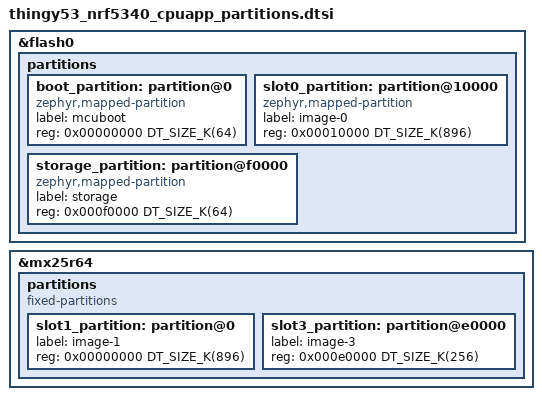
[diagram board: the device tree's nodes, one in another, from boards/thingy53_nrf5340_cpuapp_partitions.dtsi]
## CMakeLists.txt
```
#
# Copyright (c) 2022 Nordic Semiconductor ASA
#
# SPDX-License-Identifier: LicenseRef-Nordic-5-Clause
#

cmake_minimum_required(VERSION 3.20.0)

find_package(Zephyr REQUIRED HINTS $ENV{ZEPHYR_BASE})
project(nrf_wifi_scan)

target_include_directories(app PUBLIC ${ZEPHYR_BASE}/subsys/net/ip)

target_sources(app PRIVATE src/main.c)
```

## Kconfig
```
#
# Copyright (c) 2023 Nordic Semiconductor
#
# SPDX-License-Identifier: LicenseRef-Nordic-5-Clause
#

source "Kconfig.zephyr"

menu "Nordic Scan sample"

config WIFI_SCAN_INTERVAL_S
	int "Scan interval (seconds)"
	default 10
	help
	  Specifies the scan interval in seconds.

config WIFI_SCAN_BANDS_LIST
	string "Frequency bands to scan"
	default "2" if WIFI_SCAN_PROFILE_2_4GHz_ACTIVE || WIFI_SCAN_PROFILE_2_4GHz_PASSIVE || WIFI_SCAN_PROFILE_2_4GHz_NON_OVERLAP_CHAN
	default "5" if WIFI_SCAN_PROFILE_5GHz_ACTIVE || WIFI_SCAN_PROFILE_5GHz_PASSIVE || WIFI_SCAN_PROFILE_5GHz_NON_DFS_CHAN
	default "2,5" if WIFI_SCAN_PROFILE_2_4GHz_NON_OVERLAP_AND_5GHz_NON_DFS_CHAN
	default ""
	help
	  Specifies the frequency bands to scan, as follows:
	  2 - 2.4 GHz,
	  5 - 5 GHz,
	  6 - 6 GHz,
	  "" - All bands allowed by the regulatory domain.
	  Multiple bands can be specified as comma separated band values.
	  Only regulatory domain permitted values are allowed.

config WIFI_SCAN_CHAN_LIST
	string "Channel list for scan"
	default "2:1,6,11" if WIFI_SCAN_PROFILE_2_4GHz_NON_OVERLAP_CHAN
	default "5:36,40,44,48,149,153,157,161,165" if WIFI_SCAN_PROFILE_5GHz_NON_DFS_CHAN
	default "2:1,6,11_5:36,40,44,48,149,153,157,161,165" if WIFI_SCAN_PROFILE_2_4GHz_NON_OVERLAP_AND_5GHz_NON_DFS_CHAN
	default ""
	help
	  Specifies the list of channels used to perform scan.

config WIFI_SCAN_DWELL_TIME_ACTIVE
	int "Active scan dwell time"
	default 50
	range 5 1000
	help
	  Active scan dwell time (in ms) per channel.

config WIFI_SCAN_DWELL_TIME_PASSIVE
	int "Passive scan dwell time"
	default 130
	range 10 1000
	help
	  Passive scan dwell time (in ms) per channel.

# Hidden options to select the scan type
config WIFI_SCAN_TYPE_ACTIVE
	bool

config WIFI_SCAN_TYPE_PASSIVE
	bool

choice
	prompt "Choose a WiFi Scan Profile"

config WIFI_SCAN_PROFILE_DEFAULT
	bool "Scan in all bands and channels"
	help
	  Enable this profile to do Wi-Fi scan in all supported bands and channels.

config WIFI_SCAN_PROFILE_ACTIVE
	bool "Active scan"
	select WIFI_SCAN_TYPE_ACTIVE
	help
	  Enable this profile to do active scan where allowed.

config WIFI_SCAN_PROFILE_PASSIVE
	bool "Passive scan"
	select WIFI_SCAN_TYPE_PASSIVE
	help
	  Enable this profile to do passive scan on all channels.

config WIFI_SCAN_PROFILE_2_4GHz_ACTIVE
	bool "Scan in the 2.4 GHz band using active scan"
	select WIFI_SCAN_TYPE_ACTIVE
	help
	  Enable this profile to scan in the 2.4 GHz band using active scanning where allowed.

config WIFI_SCAN_PROFILE_2_4GHz_PASSIVE
	bool "Scan in the 2.4 GHz band using passive scan"
	select WIFI_SCAN_TYPE_PASSIVE
	help
	  Enable this profile to scan in the 2.4 GHz band using passive scanning on all channels.

config WIFI_SCAN_PROFILE_5GHz_ACTIVE
	bool "Scan in the 5 GHz band using active scan"
	select WIFI_SCAN_TYPE_ACTIVE
	help
	  Enable this profile to scan in the 5 GHz band using active scanning where allowed.

config WIFI_SCAN_PROFILE_5GHz_PASSIVE
	bool "Scan in the 5 GHz band using passive scan"
	select WIFI_SCAN_TYPE_PASSIVE
	help
	  Enable this profile to scan in the 5 GHz band using passive scanning on all channels.

config WIFI_SCAN_PROFILE_2_4GHz_NON_OVERLAP_CHAN
	bool "Scan only non-overlapping channels"
	help
	  Enable this profile to scan only non-overlapping channels (1, 6, 11)
	  in the 2.4 GHz band.

config WIFI_SCAN_PROFILE_5GHz_NON_DFS_CHAN
	bool "Scan only non-DFS channels"
	help
	  Enable this profile to scan only non-DFS channels (36, 40, 44,
	  48, 149, 153, 157, 161, 165) in the 5 GHz band.

config WIFI_SCAN_PROFILE_2_4GHz_NON_OVERLAP_AND_5GHz_NON_DFS_CHAN
	bool "Scan only non-overlapping and non-DFS channels"
	help
	  Enable this profile to scan only non-overlapping channels
	  (1, 6, 11) in the 2.4 GHz band and non-DFS channels (36, 40, 44,
	  48, 149, 153, 157, 161, 165) in the 5 GHz band.

endchoice

endmenu
```

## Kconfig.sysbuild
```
#
# Copyright (c) 2026 Nordic Semiconductor ASA
#
# SPDX-License-Identifier: LicenseRef-Nordic-5-Clause
#

source "${ZEPHYR_NRF_MODULE_DIR}/samples/wifi/Kconfig.sysbuild.nrf70"

source "share/sysbuild/Kconfig"
```

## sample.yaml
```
sample:
  description: Wi-Fi scan sample application
  name: Wi-Fi scan
tests:
  sample.nrf7002dk.scan:
    sysbuild: true
    build_only: true
    integration_platforms:
      - nrf7002dk/nrf5340/cpuapp
    platform_allow:
      - nrf7002dk/nrf5340/cpuapp
    tags:
      - ci_build
      - sysbuild
      - ci_samples_wifi
  sample.nrf7000_eks.scan:
    sysbuild: true
    build_only: true
    extra_args: SHIELD=nrf7002ek_nrf7000
    integration_platforms:
      - nrf5340dk/nrf5340/cpuapp
      - nrf52840dk/nrf52840
      - nrf9160dk/nrf9160/ns
      - nrf9161dk/nrf9161/ns
    platform_allow:
      - nrf5340dk/nrf5340/cpuapp
      - nrf52840dk/nrf52840
      - nrf9160dk/nrf9160/ns
      - nrf9161dk/nrf9161/ns
    tags:
      - ci_build
      - sysbuild
      - ci_samples_wifi
  sample.nrf7000_eks.raw_scan:
    sysbuild: true
    build_only: true
    extra_args:
      - SHIELD=nrf7002ek_nrf7000
      - CONFIG_WIFI_MGMT_RAW_SCAN_RESULTS=y
    integration_platforms:
      - nrf9160dk/nrf9160/ns
      - nrf9161dk/nrf9161/ns
    platform_allow:
      - nrf9160dk/nrf9160/ns
      - nrf9161dk/nrf9161/ns
      - nrf9151dk/nrf9151/ns
    tags:
      - ci_build
      - sysbuild
      - ci_samples_wifi
  sample.nrf7002_eb.thingy53.scan:
    sysbuild: true
    build_only: true
    extra_args: scan_SHIELD=nrf7002eb
    integration_platforms:
      - thingy53/nrf5340/cpuapp
    platform_allow: thingy53/nrf5340/cpuapp
    tags:
      - ci_build
      - sysbuild
      - ci_samples_wifi
  sample.thingy91x_nrf7000.scan:
    sysbuild: true
    build_only: true
    integration_platforms:
      - thingy91x/nrf9151/ns
    platform_allow: thingy91x/nrf9151/ns
    extra_args:
      - SB_CONFIG_WIFI_NRF70_SCAN_ONLY=y
    tags:
      - ci_build
      - sysbuild
      - ci_samples_wifi
  sample.nrf7002eb_interposer_p1.nrf7002eb.scan:
    sysbuild: true
    build_only: true
    extra_args:
      - scan_SHIELD="nrf7002eb_interposer_p1;nrf7002eb"
      - scan_SNIPPET=nrf70-wifi
    integration_platforms:
      - nrf54h20dk/nrf54h20/cpuapp
      - nrf54l15dk/nrf54l15/cpuapp
    platform_allow:
      - nrf54h20dk/nrf54h20/cpuapp
      - nrf54l15dk/nrf54l15/cpuapp
    tags:
      - ci_build
      - sysbuild
      - ci_samples_wifi
  sample.nrf7002eb2.scan:
    sysbuild: true
    build_only: true
    extra_args:
      - scan_SHIELD="nrf7002eb2"
      - SNIPPET=nrf70-wifi
    integration_platforms:
      - nrf54l15dk/nrf54l15/cpuapp
    platform_allow:
      - nrf54l15dk/nrf54l15/cpuapp
    tags:
      - ci_build
      - sysbuild
      - ci_samples_wifi
  sample.54lm20dk.nrf7002eb2.scan:
    sysbuild: true
    build_only: true
    extra_args:
      - scan_SHIELD="nrf7002eb2"
    integration_platforms:
      - nrf54lm20dk/nrf54lm20a/cpuapp
      - nrf54lm20dk/nrf54lm20b/cpuapp
    platform_allow:
      - nrf54lm20dk/nrf54lm20a/cpuapp
      - nrf54lm20dk/nrf54lm20b/cpuapp
    tags:
      - ci_build
      - sysbuild
      - ci_samples_wifi
  sample.nrf7120.scan:
    sysbuild: true
    build_only: true
    extra_args:
      - EXTRA_DTC_OVERLAY_FILE=${ZEPHYR_NRFXLIB_MODULE_DIR}/nrf71_wifi/bins/0.1.0/nrf7120_wifi_patch.dtsi
      - CONFIG_WIFI_NRF71_PATCH=y
    integration_platforms:
      - nrf7120dk/nrf7120/cpuapp
      - nrf7120dk/nrf7120/cpuapp/ns
    platform_allow:
      - nrf7120dk/nrf7120/cpuapp
      - nrf7120dk/nrf7120/cpuapp/ns
    tags:
      - ci_build
      - sysbuild
      - ci_samples_nrf71_wifi
```

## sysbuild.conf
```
#
# Copyright (c) 2024 Nordic Semiconductor ASA
#
# SPDX-License-Identifier: LicenseRef-Nordic-5-Clause
#

SB_CONFIG_WIFI_NRF70_SCAN_ONLY=y
```

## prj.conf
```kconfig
#
# Copyright (c) 2022 Nordic Semiconductor ASA
#
# SPDX-License-Identifier: LicenseRef-Nordic-5-Clause
#
CONFIG_WIFI=y
CONFIG_NET_L2_WIFI_MGMT=y

# System settings
CONFIG_ASSERT=y

# Networking
CONFIG_NETWORKING=y
CONFIG_NET_BUF_RX_COUNT=1
CONFIG_NET_BUF_TX_COUNT=1
CONFIG_NET_L2_ETHERNET=y
CONFIG_NET_NATIVE=n
CONFIG_NET_OFFLOAD=y

CONFIG_INIT_STACKS=y

# Memories
CONFIG_MAIN_STACK_SIZE=5200

# Debugging
CONFIG_STACK_SENTINEL=y
CONFIG_DEBUG_COREDUMP=y
CONFIG_DEBUG_COREDUMP_BACKEND_LOGGING=y
CONFIG_DEBUG_COREDUMP_MEMORY_DUMP_MIN=y

# Logging
CONFIG_LOG=y
CONFIG_PRINTK=y
# If below config is enabled, printk logs are
# buffered. For unbuffered messages, disable this.
CONFIG_LOG_PRINTK=n

# printing of scan results puts pressure on queues in new locking
# design in net_mgmt. So, use a higher timeout for a crowded
# environment.
CONFIG_NET_MGMT_EVENT_QUEUE_TIMEOUT=5000

# Raw scan Options
CONFIG_WIFI_MGMT_RAW_SCAN_RESULTS=n
CONFIG_WIFI_MGMT_RAW_SCAN_RESULTS_ONLY=n

CONFIG_WIFI_SCAN_DWELL_TIME_ACTIVE=50
CONFIG_WIFI_SCAN_DWELL_TIME_PASSIVE=130
```

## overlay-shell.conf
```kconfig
#
# Copyright (c) 2024 Nordic Semiconductor ASA
#
# SPDX-License-Identifier: LicenseRef-Nordic-5-Clause
#

CONFIG_SHELL=y
CONFIG_NET_SHELL=n
CONFIG_SHELL_BACKEND_SERIAL=y
CONFIG_SHELL_STACK_SIZE=5200
CONFIG_NRF70_UTIL=y
CONFIG_SYS_HEAP_RUNTIME_STATS=y
CONFIG_LOG=y
CONFIG_LOG_MODE_IMMEDIATE=y
CONFIG_PRINTK=y
```

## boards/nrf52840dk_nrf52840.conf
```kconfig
# Copyright (c) 2026 Nordic Semiconductor ASA
#
# SPDX-License-Identifier: LicenseRef-Nordic-5-Clause

#NRF70 specific configuration
CONFIG_WIFI_NRF70=y
```

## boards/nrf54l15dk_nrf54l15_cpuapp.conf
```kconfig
# Copyright (c) 2026 Nordic Semiconductor ASA
#
# SPDX-License-Identifier: LicenseRef-Nordic-5-Clause
#

#NRF70 specific configuration
CONFIG_WIFI_NRF70=y
```

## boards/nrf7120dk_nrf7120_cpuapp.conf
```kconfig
#
# Copyright (c) 2026 Nordic Semiconductor
#
# SPDX-License-Identifier: LicenseRef-Nordic-5-Clause
#

CONFIG_WIFI_NRF71=y
CONFIG_WIFI_USAGE_MODE_SCAN_ONLY=y
CONFIG_HEAP_MEM_POOL_SIZE=25000
```

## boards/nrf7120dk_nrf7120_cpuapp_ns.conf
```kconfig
#
# Copyright (c) 2026 Nordic Semiconductor
#
# SPDX-License-Identifier: LicenseRef-Nordic-5-Clause
#

CONFIG_NRF71_WIFI=y
CONFIG_WIFI_USAGE_MODE_SCAN_ONLY=y
CONFIG_HEAP_MEM_POOL_SIZE=25000

# Lower System ON idle current: see lib_nrf71_idle_power. Keep the
# default RAM_RETAIN_FULL tier; RAM_RETAIN_USED_ONLY has been observed
# to cause issues on Wi-Fi builds.
CONFIG_NRF71_IDLE_POWER=y
```

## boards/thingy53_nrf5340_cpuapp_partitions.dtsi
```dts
/*
 * Copyright (c) 2024 Nordic Semiconductor ASA
 *
 * SPDX-License-Identifier: LicenseRef-Nordic-5-Clause
 */

/*
 * Shared flash partition layout for thingy53/nrf5340/cpuapp.
 * Used by the main application overlay and the sysbuild mcuboot overlay.
 *
 * Internal flash (flash0):
 *   boot_partition    @ 0x000000  64 KB  MCUboot
 *   slot0_partition   @ 0x010000 896 KB  Image 0 primary
 *   storage_partition @ 0x0f0000  64 KB  Settings
 *
 * External QSPI flash (mx25r64):
 *   slot1_partition   @ 0x000000 896 KB  Image 0 secondary
 *   slot3_partition   @ 0x0e0000 256 KB  Image 1 secondary (network core)
 */

/delete-node/ &boot_partition;
/delete-node/ &slot0_partition;
/delete-node/ &slot1_partition;
/delete-node/ &storage_partition;

&flash0 {
	partitions {
		ranges;
		#address-cells = <1>;
		#size-cells = <1>;

		boot_partition: partition@0 {
			compatible = "zephyr,mapped-partition";
			label = "mcuboot";
			reg = <0x00000000 DT_SIZE_K(64)>;
		};

		slot0_partition: partition@10000 {
			compatible = "zephyr,mapped-partition";
			label = "image-0";
			reg = <0x00010000 DT_SIZE_K(896)>;
		};

		storage_partition: partition@f0000 {
			compatible = "zephyr,mapped-partition";
			label = "storage";
			reg = <0x000f0000 DT_SIZE_K(64)>;
		};
	};
};

&mx25r64 {
	status = "okay";

	partitions {
		compatible = "fixed-partitions";
		#address-cells = <1>;
		#size-cells = <1>;

		slot1_partition: partition@0 {
			label = "image-1";
			reg = <0x00000000 DT_SIZE_K(896)>;
		};

		slot3_partition: partition@e0000 {
			label = "image-3";
			reg = <0x000e0000 DT_SIZE_K(256)>;
		};
	};
};
```

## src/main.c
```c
/*
 * Copyright (c) 2022 Nordic Semiconductor ASA
 *
 * SPDX-License-Identifier: LicenseRef-Nordic-5-Clause
 */

/** @file
 * @brief WiFi scan sample
 */

#include <zephyr/logging/log.h>
LOG_MODULE_REGISTER(scan, CONFIG_LOG_DEFAULT_LEVEL);

#include <zephyr/kernel.h>
#include <stdio.h>
#include <stdlib.h>
#include <zephyr/shell/shell.h>
#include <zephyr/sys/printk.h>
#include <zephyr/init.h>

#include <zephyr/net/net_if.h>
#include <zephyr/net/wifi_mgmt.h>
#include <zephyr/net/wifi_utils.h>
#include <zephyr/net/net_event.h>
#include <zephyr/net/ethernet.h>
#include <zephyr/net/ethernet_mgmt.h>

#include "net_private.h"

#if defined(CONFIG_NRF71_IDLE_POWER)
#include <nrf71_idle_power.h>
#endif

#define WIFI_SHELL_MODULE "wifi"

/* DTS node for the Wi-Fi interface - MAC address from local-mac-address property */
#define WIFI_NODE DT_CHOSEN(zephyr_wifi)
static const uint8_t wifi_mac_addr[6] = DT_PROP_OR(WIFI_NODE, local_mac_address, {0});

#ifdef CONFIG_WIFI_MGMT_RAW_SCAN_RESULTS_ONLY
#define WIFI_SHELL_MGMT_EVENTS (NET_EVENT_WIFI_RAW_SCAN_RESULT |                \
				NET_EVENT_WIFI_SCAN_DONE)
#else
#define WIFI_SHELL_MGMT_EVENTS (NET_EVENT_WIFI_SCAN_RESULT |		\
				NET_EVENT_WIFI_SCAN_DONE |		\
				NET_EVENT_WIFI_RAW_SCAN_RESULT)
#endif
#define SCAN_TIMEOUT_MS 10000

static uint32_t scan_result;
static struct net_mgmt_event_callback wifi_shell_mgmt_cb;

K_SEM_DEFINE(scan_sem, 0, 1);

#if defined CONFIG_WIFI_NRF70_SKIP_LOCAL_ADMIN_MAC
static bool local_mac_check(const uint8_t *const mac)
{
return ((mac[0] & 0x02) ||
((mac[0] == 0x00) && (mac[1] == 0x00) && (mac[2] == 0x5E)));
}
#endif /* CONFIG_WIFI_NRF70_SKIP_LOCAL_ADMIN_MAC */

static void handle_wifi_scan_result(struct net_mgmt_event_callback *cb)
{
	const struct wifi_scan_result *entry =
		(const struct wifi_scan_result *)cb->info;
	uint8_t mac_string_buf[sizeof("xx:xx:xx:xx:xx:xx")];
	uint8_t ssid_print[WIFI_SSID_MAX_LEN + 1];

	scan_result++;

	if (scan_result == 1U) {
		printk("%-4s | %-32s %-5s | %-4s | %-4s | %-5s | %s\n",
		       "Num", "SSID", "(len)", "Chan", "RSSI", "Security", "BSSID");
	}

	strncpy(ssid_print, entry->ssid, sizeof(ssid_print) - 1);
	ssid_print[sizeof(ssid_print) - 1] = '\0';

#if defined CONFIG_WIFI_NRF70_SKIP_LOCAL_ADMIN_MAC
	__ASSERT(!local_mac_check(entry->mac), "Locally administered MAC found: %s\n", ssid_print);
#endif /* CONFIG_WIFI_NRF70_SKIP_LOCAL_ADMIN_MAC */

	printk("%-4d | %-32s %-5u | %-4u | %-4d | %-5s | %s\n",
	       scan_result, ssid_print, entry->ssid_length,
	       entry->channel, entry->rssi,
	       wifi_security_txt(entry->security),
	       ((entry->mac_length) ?
			net_sprint_ll_addr_buf(entry->mac, WIFI_MAC_ADDR_LEN, mac_string_buf,
						sizeof(mac_string_buf)) : ""));
}

#ifdef CONFIG_WIFI_MGMT_RAW_SCAN_RESULTS
static int wifi_freq_to_channel(int frequency)
{
	int channel = 0;

	if (frequency == 2484) { /* channel 14 */
		channel = 14;
	} else if ((frequency <= 2472) && (frequency >= 2412)) {
		channel = ((frequency - 2412) / 5) + 1;
	} else if ((frequency <= 5895) && (frequency >= 5180)) {
		channel = ((frequency - 5000) / 5);
	} else {
		channel = frequency;
	}

	return channel;
}

static enum wifi_frequency_bands wifi_frequency_to_band(int frequency)
{
	enum wifi_frequency_bands band = WIFI_FREQ_BAND_2_4_GHZ;

	if ((frequency  >= 2401) && (frequency <= 2495)) {
		band = WIFI_FREQ_BAND_2_4_GHZ;
	} else if ((frequency  >= 5170) && (frequency <= 5895)) {
		band = WIFI_FREQ_BAND_5_GHZ;
	}

	return band;
}

static void handle_raw_scan_result(struct net_mgmt_event_callback *cb)
{
	struct wifi_raw_scan_result *raw =
		(struct wifi_raw_scan_result *)cb->info;
	int channel;
	int band;
	int rssi;
	int i = 0;
	int raw_scan_size = raw->frame_length;
	uint8_t mac_string_buf[sizeof("xx:xx:xx:xx:xx:xx")];

	scan_result++;

	if (scan_result == 1U) {
		printk("%-4s | %-13s | %-4s |  %-15s | %-15s | %-32s\n",
		      "Num", "Channel (Band)", "RSSI", "BSSID", "Frame length", "Frame Body");
	}

	rssi = raw->rssi;
	channel = wifi_freq_to_channel(raw->frequency);
	band = wifi_frequency_to_band(raw->frequency);

	printk("%-4d | %-4u (%-6s) | %-4d | %s |      %-4d        ",
	      scan_result, channel,
	      wifi_band_txt(band),
	      rssi,
	      net_sprint_ll_addr_buf(raw->data + 10, WIFI_MAC_ADDR_LEN, mac_string_buf,
				     sizeof(mac_string_buf)), raw_scan_size);

	if (raw->frame_length > CONFIG_WIFI_MGMT_RAW_SCAN_RESULT_LENGTH) {
		raw_scan_size = CONFIG_WIFI_MGMT_RAW_SCAN_RESULT_LENGTH;
	}

	if (raw_scan_size) {
		for (i = 0; i < 32; i++) {
			printk("%02X ", *(raw->data + i));
		}
	}

	printk("\n");
}
#endif

static void handle_wifi_scan_done(struct net_mgmt_event_callback *cb)
{
	const struct wifi_status *status =
		(const struct wifi_status *)cb->info;

	if (status->status) {
		LOG_ERR("Scan request failed (%d)", status->status);
	} else {
		printk("Scan request done\n");
	}

	scan_result = 0U;
	k_sem_give(&scan_sem);
}

static void wifi_mgmt_event_handler(struct net_mgmt_event_callback *cb,
				     uint64_t mgmt_event, struct net_if *iface)
{
	switch (mgmt_event) {
	case NET_EVENT_WIFI_SCAN_RESULT:
		handle_wifi_scan_result(cb);
		break;
#ifdef CONFIG_WIFI_MGMT_RAW_SCAN_RESULTS
	case NET_EVENT_WIFI_RAW_SCAN_RESULT:
		handle_raw_scan_result(cb);
		break;
#endif
	case NET_EVENT_WIFI_SCAN_DONE:
		handle_wifi_scan_done(cb);
		break;
	default:
		break;
	}
}

static int wifi_scan(void)
{
	struct net_if *iface = net_if_get_default();
	int band_str_len;
	struct wifi_scan_params params = { 0 };

	band_str_len = sizeof(CONFIG_WIFI_SCAN_BANDS_LIST);
	if (band_str_len - 1) {
		char *buf = malloc(band_str_len);

		if (!buf) {
			LOG_ERR("Malloc Failed");
			return -EINVAL;
		}
		strcpy(buf, CONFIG_WIFI_SCAN_BANDS_LIST);
		if (wifi_utils_parse_scan_bands(buf, &params.bands)) {
			LOG_ERR("Incorrect value(s) in CONFIG_WIFI_SCAN_BANDS_LIST: %s",
					CONFIG_WIFI_SCAN_BANDS_LIST);
			free(buf);
			return -ENOEXEC;
		}
		free(buf);
	}

	if (sizeof(CONFIG_WIFI_SCAN_CHAN_LIST) - 1) {
		if (wifi_utils_parse_scan_chan(CONFIG_WIFI_SCAN_CHAN_LIST,
						params.band_chan, ARRAY_SIZE(params.band_chan))) {
			LOG_ERR("Incorrect value(s) in CONFIG_WIFI_SCAN_CHAN_LIST: %s",
					CONFIG_WIFI_SCAN_CHAN_LIST);
			return -ENOEXEC;
		}
	}

	params.dwell_time_passive = CONFIG_WIFI_SCAN_DWELL_TIME_PASSIVE;
	params.dwell_time_active = CONFIG_WIFI_SCAN_DWELL_TIME_ACTIVE;

	if (IS_ENABLED(CONFIG_WIFI_SCAN_TYPE_PASSIVE)) {
		params.scan_type = WIFI_SCAN_TYPE_PASSIVE;
	} else {
		params.scan_type = WIFI_SCAN_TYPE_ACTIVE;
	}

	if (net_mgmt(NET_REQUEST_WIFI_SCAN, iface, &params,
			sizeof(struct wifi_scan_params))) {
		LOG_ERR("Scan request failed");
		return -ENOEXEC;
	}

	printk("Scan requested\n");

	k_sem_take(&scan_sem, K_MSEC(SCAN_TIMEOUT_MS));

	return 0;
}

static bool is_mac_addr_set(struct net_if *iface)
{
	struct net_linkaddr *linkaddr = net_if_get_link_addr(iface);
	struct net_eth_addr wifi_addr;

	if (!linkaddr || linkaddr->len != WIFI_MAC_ADDR_LEN) {
		return false;
	}

	memcpy(wifi_addr.addr, linkaddr->addr, WIFI_MAC_ADDR_LEN);

	return net_eth_is_addr_valid(&wifi_addr);
}

int main(void)
{
	scan_result = 0U;

	net_mgmt_init_event_callback(&wifi_shell_mgmt_cb,
				     wifi_mgmt_event_handler,
				     WIFI_SHELL_MGMT_EVENTS);

	net_mgmt_add_event_callback(&wifi_shell_mgmt_cb);

	k_sleep(K_SECONDS(1));
	printk("Starting %s with CPU frequency: %d MHz\n", CONFIG_BOARD, SystemCoreClock / MHZ(1));

	/* Set MAC from DTS if interface has no valid MAC and DTS provides one */
	if (!is_mac_addr_set(net_if_get_default())) {
		if (!net_eth_is_addr_valid((struct net_eth_addr *)wifi_mac_addr)) {
			LOG_ERR("No valid MAC address: OTP not programmed and no valid "
				"local-mac-address in DTS");
			return -EINVAL;
		}

		struct net_if *iface = net_if_get_default();
		int ret;
		struct ethernet_req_params params;

		/* Set a local MAC address from DTS overlay */
		if (net_if_is_admin_up(iface)) {
			ret = net_if_down(iface);
			if (ret < 0 && ret != -EALREADY) {
				LOG_ERR("Cannot bring down iface (%d)", ret);
				return ret;
			}
		}

		memcpy(params.mac_address.addr, wifi_mac_addr, sizeof(wifi_mac_addr));

		net_mgmt(NET_REQUEST_ETHERNET_SET_MAC_ADDRESS, iface,
			 &params, sizeof(params));

		ret = net_if_up(iface);
		if (ret < 0 && ret != -EALREADY) {
			LOG_ERR("Cannot bring up iface (%d)", ret);
			return ret;
		}

		LOG_INF("OTP not programmed, using MAC from DTS: %s", net_sprint_ll_addr(
							net_if_get_link_addr(iface)->addr,
							net_if_get_link_addr(iface)->len));
	}

	while (1) {
		wifi_scan();
#if defined(CONFIG_NRF71_IDLE_POWER)
		nrf71_idle_power_suspend_console();
#endif
		k_sleep(K_SECONDS(CONFIG_WIFI_SCAN_INTERVAL_S));
#if defined(CONFIG_NRF71_IDLE_POWER)
		nrf71_idle_power_resume_console();
#endif
	}

	return 0;
}
```
